VERSION ""

NS_ :

BS_:

BU_: Tester RearECU MyECU

BO_ 512 msg_Transmit: 1 MyECU
 SG_ Signal_SwitchRearInteriorLight : 0|8@1+ (1,0) [0|255] ""  RearECU

BO_ 614 msg_TxMulti100: 8 MyECU
 SG_ Signal_TxMulti_0_0 m0 : 8|2@1+ (1,0) [0|3] "" Vector__XXX
 SG_ Signal_TxMulti1_4 m1 : 40|8@1+ (1,0) [0|255] ""  RearECU
 SG_ Signal_TxMulti1_3 m1 : 32|8@1+ (1,0) [0|255] ""  RearECU
 SG_ Signal_TxMulti1_2 m1 : 24|8@1+ (1,0) [0|255] ""  RearECU
 SG_ Signal_TxMulti1_1 m1 : 16|8@1+ (1,0) [0|255] ""  RearECU
 SG_ Signal_TxMulti1_0 m1 : 8|8@1+ (1,0) [0|255] ""  RearECU
 SG_ Signal_TxMulti0_3 m0 : 32|8@1+ (1,0) [0|255] ""  RearECU
 SG_ Signal_TxMulti0_2 m0 : 24|4@1+ (1,0) [0|15] ""  RearECU
 SG_ Signal_TxMulti0_1 m0 : 16|8@1+ (1,0) [0|255] ""  RearECU
 SG_ Signal_TxMultiplexor M : 0|3@1+ (1,0) [0|7] ""  RearECU

BO_ 1796 msg_XCP_Response: 8 MyECU
 SG_ Signal_XCP_Response : 0|64@1+ (1,0) [0|1.844674407371E+019] ""  RearECU

BO_ 1795 msg_XCP_Request: 8 RearECU
 SG_ Signal_XCP_Request : 0|64@1+ (1,0) [0|1.844674407371E+019] ""  MyECU

BO_ 616 msg_TxCycle10: 8 MyECU
 SG_ Signal_TxCycle10 : 0|32@1+ (1,0) [0|4294967295] ""  RearECU

BO_ 1558 msg_diag_Uudt_Response_MyECU: 8 MyECU
 SG_ Signal_DiagPeriodicResp : 0|64@1+ (1,0) [0|0] ""  Tester

BO_ 1025 msg_nm_RearECU: 8 RearECU
 SG_ Signal_Nm_RearECU : 0|64@1+ (1,0) [0|1.8446744074E+019] "" Vector__XXX

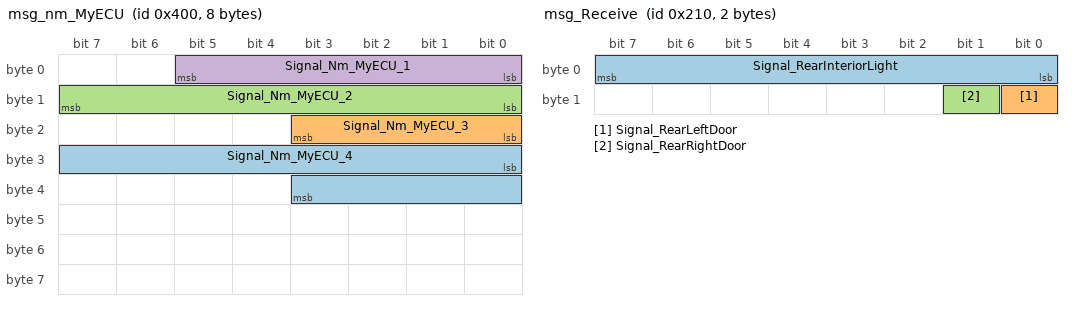
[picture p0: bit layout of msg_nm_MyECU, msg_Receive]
BO_ 1024 msg_nm_MyECU: 8 MyECU
 SG_ Signal_Nm_MyECU_4 : 24|12@1+ (1,0) [0|4095] "" Vector__XXX
 SG_ Signal_Nm_MyECU_3 : 16|4@1+ (1,0) [0|15] "" Vector__XXX
 SG_ Signal_Nm_MyECU_2 : 8|8@1+ (1,0) [0|255] "" Vector__XXX
 SG_ Signal_Nm_MyECU_1 : 0|6@1+ (1,0) [0|63] "" Vector__XXX

BO_ 1554 msg_diag_Response_MyECU: 8 MyECU
 SG_ Signal_DiagResponseMyECU : 0|64@1+ (1,0) [0|1.8446744074E+019] ""  Tester

BO_ 1552 msg_diag_Request_MyECU: 8 Tester
 SG_ Signal_DiagRequestMyECU : 0|64@1+ (1,0) [0|1.8446744074E+019] ""  MyECU

BO_ 1556 msg_diag_RequestGlobal: 8 Tester
 SG_ Signal_DiagRequestGlobal : 0|64@1+ (1,0) [0|1.8446744074E+019] ""  MyECU

BO_ 528 msg_Receive: 2 RearECU
 SG_ Signal_RearInteriorLight : 0|8@1+ (1,0) [0|255] ""  MyECU
 SG_ Signal_RearLeftDoor : 8|1@1+ (1,0) [0|1] ""  MyECU
 SG_ Signal_RearRightDoor : 9|1@1+ (1,0) [0|1] ""  MyECU

BA_DEF_ BO_  "DiagUUDTResponse" ENUM  "No","Yes";
BA_DEF_ BO_  "GenMsgCycleTime" INT 0 0;
BA_DEF_ BO_  "GenMsgSendType" ENUM  "Cyclic","NotUsed","NotUsed","NotUsed","NotUsed","NotUsed","NotUsed","NotUsed","NoMsgSendType";
BA_DEF_ SG_  "GenSigStartValue" INT 0 0;
BA_DEF_ SG_  "GenSigCycleTimeActive" INT 0 0;
BA_DEF_ SG_  "GenSigCycleTime" INT 0 0;
BA_DEF_ SG_  "GenSigSendType" ENUM  "Cyclic","OnWrite","NotUsed","OnChange","NotUsed","NotUsed","NotUsed","NoSigSendType";
BA_DEF_  "Baudrate" INT 0 1000000;
BA_DEF_  "BusType" STRING ;
BA_DEF_  "NmType" STRING ;
BA_DEF_  "Manufacturer" STRING ;
BA_DEF_  "NmAsrWaitBusSleepTime" INT 0 65535;
BA_DEF_  "NmAsrTimeoutTime" INT 0 65535;
BA_DEF_  "NmAsrRepeatMessageTime" INT 0 65535;
BA_DEF_ BU_  "NmAsrNodeIdentifier" INT 0 255;
BA_DEF_ BU_  "NmAsrNode" ENUM  "no","yes";
BA_DEF_  "NmAsrMessageCount" INT 0 256;
BA_DEF_ BO_  "NmAsrMessage" ENUM  "no","yes";
BA_DEF_ BU_  "NmAsrCanMsgReducedTime" INT 0 65535;
BA_DEF_  "NmAsrCanMsgCycleTime" INT 0 65535;
BA_DEF_  "NmAsrBaseAddress" HEX 0 65535;
BA_DEF_ BU_  "ILUsed" ENUM  "no","yes";
BA_DEF_ BO_  "GenMsgILSupport" ENUM  "no","yes";
BA_DEF_ BO_  "DiagState" ENUM  "No","Yes";
BA_DEF_ BO_  "DiagResponse" ENUM  "No","Yes";
BA_DEF_ BO_  "DiagRequest" ENUM  "No","Yes";
BA_DEF_DEF_  "DiagUUDTResponse" "No";
BA_DEF_DEF_  "GenMsgCycleTime" 0;
BA_DEF_DEF_  "GenMsgSendType" "NoMsgSendType";
BA_DEF_DEF_  "GenSigStartValue" 0;
BA_DEF_DEF_  "GenSigCycleTimeActive" 0;
BA_DEF_DEF_  "GenSigCycleTime" 0;
BA_DEF_DEF_  "GenSigSendType" "Cyclic";
BA_DEF_DEF_  "Baudrate" 500000;
BA_DEF_DEF_  "BusType" "";
BA_DEF_DEF_  "NmType" "";
BA_DEF_DEF_  "Manufacturer" "Vector";
BA_DEF_DEF_  "NmAsrWaitBusSleepTime" 750;
BA_DEF_DEF_  "NmAsrTimeoutTime" 1000;
BA_DEF_DEF_  "NmAsrRepeatMessageTime" 400;
BA_DEF_DEF_  "NmAsrNodeIdentifier" 0;
BA_DEF_DEF_  "NmAsrNode" "yes";
BA_DEF_DEF_  "NmAsrMessageCount" 64;
BA_DEF_DEF_  "NmAsrMessage" "no";
BA_DEF_DEF_  "NmAsrCanMsgReducedTime" 50;
BA_DEF_DEF_  "NmAsrCanMsgCycleTime" 100;
BA_DEF_DEF_  "NmAsrBaseAddress" 1024;
BA_DEF_DEF_  "ILUsed" "yes";
BA_DEF_DEF_  "GenMsgILSupport" "yes";
BA_DEF_DEF_  "DiagState" "No";
BA_DEF_DEF_  "DiagResponse" "No";
BA_DEF_DEF_  "DiagRequest" "No";
BA_ "NmType" "NmAsr";
BA_ "BusType" "CAN";
BA_ "Baudrate" 250000;
BA_ "NmAsrNode" BU_ Tester 0;
BA_ "NmAsrNodeIdentifier" BU_ RearECU 1;
BA_ "GenMsgCycleTime" BO_ 512 100;
BA_ "GenMsgSendType" BO_ 512 0;
BA_ "GenMsgSendType" BO_ 614 0;
BA_ "GenMsgCycleTime" BO_ 614 100;
BA_ "GenMsgILSupport" BO_ 1796 0;
BA_ "GenMsgILSupport" BO_ 1795 0;
BA_ "GenMsgSendType" BO_ 616 0;
BA_ "GenMsgCycleTime" BO_ 616 10;
BA_ "DiagUUDTResponse" BO_ 1558 1;
BA_ "GenMsgILSupport" BO_ 1558 0;
BA_ "GenMsgILSupport" BO_ 1025 0;
BA_ "NmAsrMessage" BO_ 1025 1;
BA_ "GenMsgSendType" BO_ 1025 0;
BA_ "GenMsgCycleTime" BO_ 1025 100;
BA_ "GenMsgILSupport" BO_ 1024 0;
BA_ "NmAsrMessage" BO_ 1024 1;
BA_ "GenMsgSendType" BO_ 1024 0;
BA_ "GenMsgCycleTime" BO_ 1024 100;
BA_ "DiagResponse" BO_ 1554 1;
BA_ "GenMsgILSupport" BO_ 1554 0;
BA_ "GenMsgSendType" BO_ 1554 0;
BA_ "GenMsgCycleTime" BO_ 1554 100;
BA_ "DiagRequest" BO_ 1552 1;
BA_ "GenMsgILSupport" BO_ 1552 0;
BA_ "GenMsgSendType" BO_ 1552 0;
BA_ "GenMsgCycleTime" BO_ 1552 100;
BA_ "DiagState" BO_ 1556 1;
BA_ "GenMsgILSupport" BO_ 1556 0;
BA_ "GenMsgSendType" BO_ 1556 0;
BA_ "GenMsgCycleTime" BO_ 1556 100;
BA_ "GenMsgSendType" BO_ 528 0;
BA_ "GenMsgCycleTime" BO_ 528 100;
BA_ "GenSigCycleTimeActive" SG_ 512 Signal_SwitchRearInteriorLight 100;
BA_ "GenSigCycleTime" SG_ 512 Signal_SwitchRearInteriorLight 100;
BA_ "GenSigCycleTime" SG_ 614 Signal_TxMulti_0_0 100;
BA_ "GenSigCycleTime" SG_ 614 Signal_TxMulti1_4 100;
BA_ "GenSigStartValue" SG_ 614 Signal_TxMulti1_4 20;
BA_ "GenSigCycleTime" SG_ 614 Signal_TxMulti1_3 100;
BA_ "GenSigStartValue" SG_ 614 Signal_TxMulti1_3 19;
BA_ "GenSigCycleTime" SG_ 614 Signal_TxMulti1_2 100;
BA_ "GenSigStartValue" SG_ 614 Signal_TxMulti1_2 18;
BA_ "GenSigCycleTime" SG_ 614 Signal_TxMulti1_1 100;
BA_ "GenSigStartValue" SG_ 614 Signal_TxMulti1_1 17;
BA_ "GenSigCycleTime" SG_ 614 Signal_TxMulti1_0 100;
BA_ "GenSigStartValue" SG_ 614 Signal_TxMulti1_0 16;
BA_ "GenSigCycleTime" SG_ 614 Signal_TxMulti0_3 100;
BA_ "GenSigStartValue" SG_ 614 Signal_TxMulti0_3 3;
BA_ "GenSigCycleTime" SG_ 614 Signal_TxMulti0_2 100;
BA_ "GenSigStartValue" SG_ 614 Signal_TxMulti0_2 2;
BA_ "GenSigCycleTime" SG_ 614 Signal_TxMulti0_1 100;
BA_ "GenSigStartValue" SG_ 614 Signal_TxMulti0_1 1;
BA_ "GenSigCycleTime" SG_ 614 Signal_TxMultiplexor 100;
BA_ "GenSigSendType" SG_ 1796 Signal_XCP_Response 7;
BA_ "GenSigSendType" SG_ 1795 Signal_XCP_Request 7;
BA_ "GenSigCycleTime" SG_ 616 Signal_TxCycle10 10;
BA_ "GenSigSendType" SG_ 1558 Signal_DiagPeriodicResp 7;
BA_ "GenSigCycleTime" SG_ 1025 Signal_Nm_RearECU 100;
BA_ "GenSigCycleTimeActive" SG_ 1025 Signal_Nm_RearECU 100;
BA_ "GenSigCycleTimeActive" SG_ 1024 Signal_Nm_MyECU_4 100;
BA_ "GenSigCycleTime" SG_ 1024 Signal_Nm_MyECU_4 100;
BA_ "GenSigCycleTimeActive" SG_ 1024 Signal_Nm_MyECU_3 100;
BA_ "GenSigCycleTime" SG_ 1024 Signal_Nm_MyECU_3 100;
BA_ "GenSigCycleTimeActive" SG_ 1024 Signal_Nm_MyECU_2 100;
BA_ "GenSigCycleTime" SG_ 1024 Signal_Nm_MyECU_2 100;
BA_ "GenSigCycleTime" SG_ 1024 Signal_Nm_MyECU_1 100;
BA_ "GenSigCycleTimeActive" SG_ 1024 Signal_Nm_MyECU_1 100;
BA_ "GenSigSendType" SG_ 1554 Signal_DiagResponseMyECU 7;
BA_ "GenSigSendType" SG_ 1552 Signal_DiagRequestMyECU 7;
BA_ "GenSigSendType" SG_ 1556 Signal_DiagRequestGlobal 7;
BA_ "GenSigCycleTime" SG_ 528 Signal_RearInteriorLight 100;
BA_ "GenSigCycleTimeActive" SG_ 528 Signal_RearInteriorLight 100;
BA_ "GenSigCycleTime" SG_ 528 Signal_RearLeftDoor 100;
BA_ "GenSigCycleTimeActive" SG_ 528 Signal_RearLeftDoor 100;
BA_ "GenSigCycleTime" SG_ 528 Signal_RearRightDoor 100;
BA_ "GenSigCycleTimeActive" SG_ 528 Signal_RearRightDoor 100;
